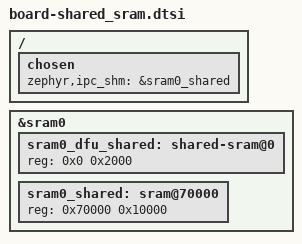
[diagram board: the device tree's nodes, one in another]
/* Default shared SRAM planning when building for nRF5340.
 * This file is included by both nRF5340 CPUAPP (Application MCU)
 * and nRF5340 CPUNET (Network MCU).
 * - 64 kB SRAM allocated as Shared memory (sram0_shared)
 * - Region defined after the image SRAM of Application MCU
 */

/ {
	chosen {
		/* Shared memory reserved for the inter-processor communication */
		zephyr,ipc_shm = &sram0_shared;
	};
};

&sram0 {
	sram0_dfu_shared: shared-sram@0 {
		reg = <0x0 0x2000>;
	};

	sram0_shared: sram@70000 {
		/* Last 64 kB of sram0 */
		reg = <0x70000 0x10000>;
	};
};
